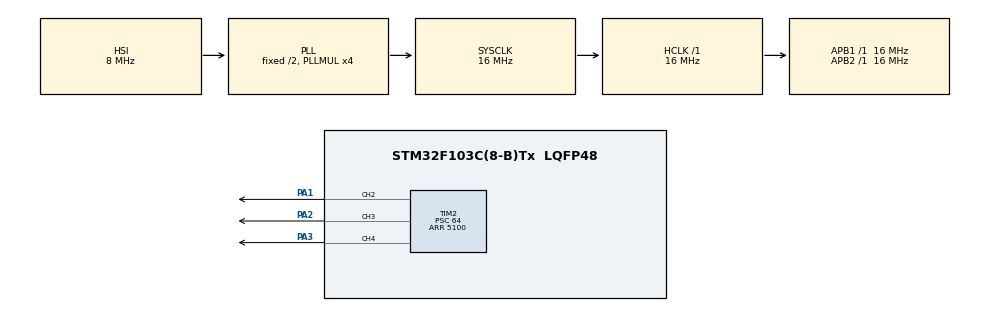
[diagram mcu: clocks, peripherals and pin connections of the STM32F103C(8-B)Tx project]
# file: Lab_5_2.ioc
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Mcu.Family=STM32F1
Mcu.Name=STM32F103C(8-B)Tx
Mcu.Package=LQFP48
NVIC.PriorityGroup=NVIC_PRIORITYGROUP_4
NVIC.TIM3_IRQn=true\:0\:0\:false\:true\:true\:1\:true\:true
NVIC.TIM4_IRQn=true\:0\:0\:false\:true\:true\:2\:true\:true
PA1.Signal=S_TIM2_CH2
PA13.Mode=Serial_Wire
PA13.Signal=SYS_JTMS-SWDIO
PA14.Mode=Serial_Wire
PA14.Signal=SYS_JTCK-SWCLK
PA2.Signal=S_TIM2_CH3
PA3.Signal=S_TIM2_CH4
ProjectManager.HeapSize=0x200
ProjectManager.StackSize=0x400
ProjectManager.TargetToolchain=STM32CubeIDE
RCC.AHBFreq_Value=16000000
RCC.APB1Freq_Value=16000000
RCC.APB1TimFreq_Value=16000000
RCC.APB2Freq_Value=16000000
RCC.APB2TimFreq_Value=16000000
RCC.HCLKFreq_Value=16000000
RCC.PLLMUL=RCC_PLL_MUL4
RCC.SYSCLKFreq_VALUE=16000000
RCC.SYSCLKSource=RCC_SYSCLKSOURCE_PLLCLK
RCC.USBFreq_Value=16000000
SH.S_TIM2_CH2.0=TIM2_CH2,PWM Generation2 CH2
SH.S_TIM2_CH3.0=TIM2_CH3,PWM Generation3 CH3
SH.S_TIM2_CH4.0=TIM2_CH4,PWM Generation4 CH4
TIM2.Channel-PWM\ Generation2\ CH2=TIM_CHANNEL_2
TIM2.Channel-PWM\ Generation3\ CH3=TIM_CHANNEL_3
TIM2.Channel-PWM\ Generation4\ CH4=TIM_CHANNEL_4
TIM2.Period=5100
TIM2.Prescaler=64
TIM2.Pulse-PWM\ Generation2\ CH2=600
TIM2.Pulse-PWM\ Generation3\ CH3=255
TIM2.Pulse-PWM\ Generation4\ CH4=800
TIM3.Period=10
TIM3.Prescaler=16000
TIM3.TIM_MasterOutputTrigger=TIM_TRGO_UPDATE
TIM4.Period=10
TIM4.Prescaler=16000
TIM4.TIM_MasterOutputTrigger=TIM_TRGO_UPDATE
VP_TIM2_VS_ClockSourceINT.Mode=Internal
VP_TIM3_VS_ClockSourceINT.Mode=Internal
VP_TIM4_VS_ClockSourceINT.Mode=Internal
board=custom

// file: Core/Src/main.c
/* USER CODE BEGIN Header */
/**
  ******************************************************************************
  * @file           : main.c
  * @brief          : Main program body
  ******************************************************************************
  * @attention
  *
  * <h2><center>&copy; Copyright (c) 2021 STMicroelectronics.
  * All rights reserved.</center></h2>
  *
  * This software component is licensed by ST under BSD 3-Clause license,
  * the "License"; You may not use this file except in compliance with the
  * License. You may obtain a copy of the License at:
  *                        opensource.org/licenses/BSD-3-Clause
  *
  ******************************************************************************
  */
/* USER CODE END Header */
#include "main.h"
#include "tim.h"
#include "gpio.h"

void SystemClock_Config(void);
static void MX_NVIC_Init(void);

int main(void)
{

  /* MCU Configuration--------------------------------------------------------*/

  /* Reset of all peripherals, Initializes the Flash interface and the Systick. */
  HAL_Init();

  /* Configure the system clock */
  SystemClock_Config();

  /* Initialize all configured peripherals */
  MX_GPIO_Init();
  MX_TIM2_Init();
  MX_TIM3_Init();
  MX_TIM4_Init();

  /* Initialize interrupts */
  MX_NVIC_Init();
  /* USER CODE BEGIN 2 */
  HAL_TIM_PWM_Start(&htim2, TIM_CHANNEL_2);
  HAL_TIM_PWM_Start(&htim2, TIM_CHANNEL_3);
  HAL_TIM_PWM_Start(&htim2, TIM_CHANNEL_4);
  HAL_TIM_Base_Start_IT(&htim3);
  HAL_TIM_Base_Start_IT(&htim4);
  /* USER CODE END 2 */

  /* Infinite loop */
    while (1)
    {

    }
}

void SystemClock_Config(void)
{
  RCC_OscInitTypeDef RCC_OscInitStruct = {0};
  RCC_ClkInitTypeDef RCC_ClkInitStruct = {0};

  /** Initializes the RCC Oscillators according to the specified parameters
  * in the RCC_OscInitTypeDef structure.
  */
  RCC_OscInitStruct.OscillatorType = RCC_OSCILLATORTYPE_HSI;
  RCC_OscInitStruct.HSIState = RCC_HSI_ON;
  RCC_OscInitStruct.HSICalibrationValue = RCC_HSICALIBRATION_DEFAULT;
  RCC_OscInitStruct.PLL.PLLState = RCC_PLL_ON;
  RCC_OscInitStruct.PLL.PLLSource = RCC_PLLSOURCE_HSI_DIV2;
  RCC_OscInitStruct.PLL.PLLMUL = RCC_PLL_MUL4;
  if (HAL_RCC_OscConfig(&RCC_OscInitStruct) != HAL_OK)
  {
    Error_Handler();
  }
  /** Initializes the CPU, AHB and APB buses clocks
  */
  RCC_ClkInitStruct.ClockType = RCC_CLOCKTYPE_HCLK|RCC_CLOCKTYPE_SYSCLK
                              |RCC_CLOCKTYPE_PCLK1|RCC_CLOCKTYPE_PCLK2;
  RCC_ClkInitStruct.SYSCLKSource = RCC_SYSCLKSOURCE_PLLCLK;
  RCC_ClkInitStruct.AHBCLKDivider = RCC_SYSCLK_DIV1;
  RCC_ClkInitStruct.APB1CLKDivider = RCC_HCLK_DIV1;
  RCC_ClkInitStruct.APB2CLKDivider = RCC_HCLK_DIV1;

  if (HAL_RCC_ClockConfig(&RCC_ClkInitStruct, FLASH_LATENCY_0) != HAL_OK)
  {
    Error_Handler();
  }
}

/**
  * @brief NVIC Configuration.
  * @retval None
  */
static void MX_NVIC_Init(void)
{
  /* TIM3_IRQn interrupt configuration */
  HAL_NVIC_SetPriority(TIM3_IRQn, 0, 0);
  HAL_NVIC_EnableIRQ(TIM3_IRQn);
  /* TIM4_IRQn interrupt configuration */
  HAL_NVIC_SetPriority(TIM4_IRQn, 0, 0);
  HAL_NVIC_EnableIRQ(TIM4_IRQn);
}

/* USER CODE BEGIN 4 */
int myPulsePWM = 255;
int myPulsePWM1 = 600;
int flag = 0;
void HAL_TIM_PeriodElapsedCallback(TIM_HandleTypeDef *htim)
{
	 if(htim->Instance == TIM3){
		//myPulsePWM = 0;
		if(myPulsePWM < 600 && flag == 0){
	  		  myPulsePWM += 1;
	  		 __HAL_TIM_SetCompare(&htim2, TIM_CHANNEL_3, myPulsePWM);
		}
		if(myPulsePWM >= 600) myPulsePWM = 255;
		/*if(myPulsePWM > 255 && flag == 1){
	  		  myPulsePWM -= 1;
	  		  __HAL_TIM_SetCompare(&htim2, TIM_CHANNEL_3, myPulsePWM);
		}
		if(myPulsePWM <= 255)flag = 0;*/
	}
	if(htim->Instance == TIM4){
		if(myPulsePWM1 > 255){
			  		  myPulsePWM1 -= 10;
			  		  __HAL_TIM_SetCompare(&htim2, TIM_CHANNEL_2, myPulsePWM1);
			}
				if(myPulsePWM1 <= 255)myPulsePWM1 = 600;

	}

}
/* USER CODE END 4 */

void Error_Handler(void)
{
  __disable_irq();
  while (1)
  {
  }
}

/************************ (C) COPYRIGHT STMicroelectronics *****END OF FILE****/
